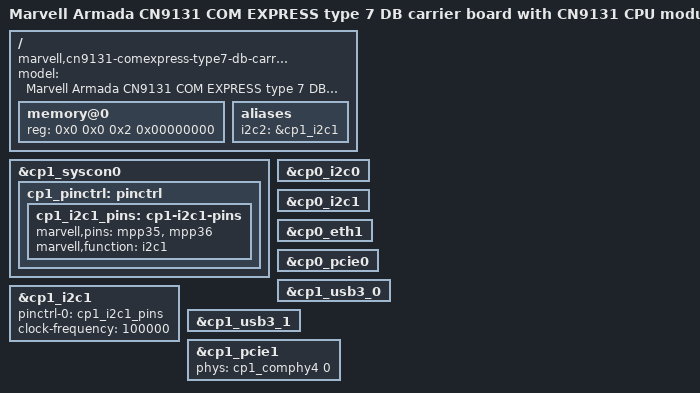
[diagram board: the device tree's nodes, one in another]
// SPDX-License-Identifier: (GPL-2.0+ OR MIT)
/*
 * Copyright (C) 2023 Marvell International Ltd.
 *
 * Device tree for the CN9131 COM Express Type 7 DB carrier board.
 */

#include "cn9131-comexpress-type7-interposer.dtsi"

/ {
	model = "Marvell Armada CN9131 COM EXPRESS type 7 DB carrier board with CN9131 CPU module";
	compatible = "marvell,cn9131-comexpress-type7-db-carrier",
		     "marvell,cn9131-cpu-module", "marvell,cn9131",
		     "marvell,armada-ap807-quad", "marvell,armada-ap807";

	memory@0 {
		device_type = "memory";
		reg = <0x0 0x0 0x2 0x00000000>;
	};

	aliases {
		i2c2 = &cp1_i2c1;
	};
};

&cp1_syscon0 {
	cp1_pinctrl: pinctrl {
		cp1_i2c1_pins: cp1-i2c1-pins {
			marvell,pins = "mpp35", "mpp36";
			marvell,function = "i2c1";
		};
	};
};

&cp1_i2c1 {
	pinctrl-names = "default";
	pinctrl-0 = <&cp1_i2c1_pins>;
	clock-frequency = <100000>;
	status = "okay";
};

&cp0_i2c0 {
	status = "okay";
};

&cp0_i2c1 {
	status = "okay";
};

&cp0_eth1 {
	status = "okay";
};

&cp0_pcie0 {
	status = "okay";
};

&cp1_usb3_0 {
	status = "okay";
};

&cp1_usb3_1 {
	status = "okay";
};

&cp1_pcie1 {
	phys = <&cp1_comphy4 0>;
	status = "okay";
};
